# AE822FA0E5597LS0_CM55_HP_View register map
Vendor: Alif Semiconductor; Series: E8; File version: 1.0
CPU: CM55 r1p0, selectable endian, MPU, FPU, double-precision FPU, DSP, VTOR, 8 interrupt priority bits, 1 SAU regions
Registers are 32-bit, read-write, reset 0x0 unless marked. A register's access mark holds for its fields unless they carry their own. Offsets are from the block's base; [hi:lo] are bit positions; {n}, {i} and the like mark numbered series; 'fields as' and 'values as' point back to an identical list.

## LPI2S
Base 0x43001000
Same registers: I2S0 0x49014000, I2S1 0x49015000, I2S2 0x49016000, I2S3 0x49017000
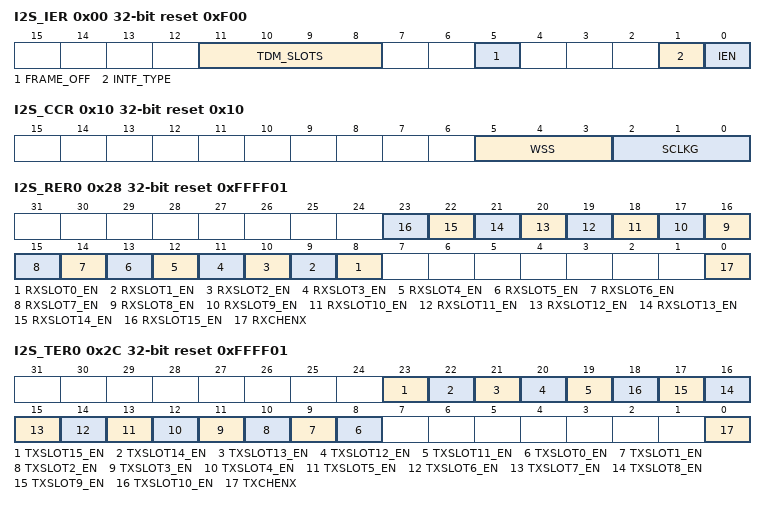
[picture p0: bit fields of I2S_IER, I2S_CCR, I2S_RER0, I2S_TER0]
0x00 I2S_IER reset 0xF00 — I2S Enable Register
  [11:8] TDM_SLOTS — TDM Slots. These bits are used to program the number of receive and transmit slots in a TDM frame. Programmed number of slots must be less than or equal to the number of slots in a TDM frame - 1. If the selected number of slots is greater than the number of slots in a TDM frame - 1, the number of slots defaults back to the number of slots in a TDM frame - 1. The I2S module must be disabled prior to any changes in this field (I2S_IER[IEN] = 0x0).
    0=1 slot in a TDM frame; {v}={v+1} slots in a TDM frame (v=1..15)
  [5] FRAME_OFF — Frame Offset. This bit specifies the TDM Interface frame offset. The I2S module must be disabled prior to any changes in this field (I2S_IER[IEN] = 0x0).
    0=0 SCLK cycle; 1=1 SCLK cycle
  [1] INTF_TYPE — I2S Audio Interface Type. The I2S module must be disabled prior to any changes in this field (I2S_IER[IEN] = 0x0).
    0=Standard I2S Interface; 1=TDM Interface
  [0] IEN — I2S Enable. This bit enables or disables the I2S module. Disabling this bit (I2S_IER[IEN] = 0x0) overrides any other block or channel enables, and flushes all FIFOs. For more information about how this bit affects the other I2S blocks, refer to Section I2S Enable.
    0=I2S disabled; 1=I2S enabled
0x04 I2S_IRER — I2S Receiver Block Enable Register
  [0] RXEN — Receiver Block Enable. This bit enables or disables the Receiver block. Disabling this bit (I2S_IRER[RXEN] = 0x0) overrides the receive channel enables. For more information about the Receiver block, refer to Section I2S as a Receiver. Note: When the I2S module is configured with TDM Interface support, the number of channels are always fixed to one and it is always enabled.
    0=Receiver disabled; 1=Receiver enabled
0x08 I2S_ITER — I2S Transmitter Block Enable Register
  [0] TXEN — Transmitter Block Enable. This bit enables or disables the Transmitter block. Disabling this bit (I2S_ITER[TXEN] = 0x0) overrides the transmit channel enables. For more information about the Transmitter block, refer to Section I2S as a Transmitter. Note: When the I2S module is configured with TDM Interface support, the number of channels are always fixed to one and it is always enabled.
    0=Transmitter disabled; 1=Transmitter enabled
0x0C I2S_CER — Clock Enable Register
  [0] CLKEN — Clock Generation Enable or Disable. This bit enables or disables the clock generation signals when the I2S module is a master: SCLK_EN, WS_OUT, and SCLK_GATE. For more information about clock generation, refer to Section I2S Clocks.
    0=Clock generation disabled; 1=Clock generation enabled
0x10 I2S_CCR reset 0x10 — Clock Configuration Register
  [5:3] WSS — Word Select Size. This bit field is used to program the number of SCLK cycles for which the word select line (WS_OUT) stays in the left or right sample mode. The I2S Clock Generation block must be disabled (I2S_CER[CLKEN] = 0x0) prior to any changes in this value.
    0=16 SCLK cycles; 1=24 SCLK cycles; 2=32 SCLK cycles; 3=64 SCLK cycles; 4=128 SCLK cycles; 5=256 SCLK cycles
  [2:0] SCLKG — SCLK Gating. This bit field is used to program the gating of SCLK. The programmed gating value must be less than or equal to the largest configured (programmed) audio resolution to prevent the truncating of Rx/Tx data. The I2S Clock Generation block must be disabled (I2S_CER[CLKEN] = 0x0) before making any changes in this value.
    0=Clock gating is disabled; 1=Gating after 12 SCLK cycles; 2=Gating after 16 SCLK cycles; 3=Gating after 20 SCLK cycles; 4=Gating after 24 SCLK cycles; 5=Gating after 32 SCLK cycles
0x14 I2S_RXFFR — Receiver Block FIFO Reset Register
  [0] RXFFR wo — Receiver FIFO Reset. Writing a 0x1 to this bit flushes all the Rx FIFOs (this is a self clearing bit). The Receiver block must be disabled before writing to this bit.
    0=Does not flush the Rx FIFO; 1=Flushes the Rx FIFO
0x18 I2S_TXFFR — Transmitter Block FIFO Reset Register
  [0] TXFFR wo — Transmitter FIFO Reset. Writing a 0x1 to this bit flushes all the Tx FIFOs (this is a self clearing bit). The Transmitter block must be disabled prior to writing this bit.
    0=Does not flush the Tx FIFO; 1=Flushes the Tx FIFO
0x1C I2S_SR ro reset 0x1 — Status Register
  [0] TFE — Transmit FIFO Empty. TDM mode (I2S_IER[INTF_TYPE] = 1): When all of the enabled transmit slot FIFOs become completely empty, this bit is set. When any one of the enabled transmit FIFOs contains one or more valid entries, this bit is cleared. Note: When the I2S module is transmitting the last TDM frame, this bit is set along with the last slot in that frame - as the data is popped with it. Hence, user must wait for one slot length, 32 cycles (to ensure that last slot data is transmitted), to disable the interface. I2S mode (I2S_IER[INTF_TYPE] = 0x0): When left and right transmit FIFOs are completely empty, this bit is set. When the left or right transmit FIFO contains one or more valid entries, this bit is cleared. Note: When the I2S module is transmitting the last I2S frame, this bit is set along with the right data transmission in that frame - as the data is popped with it. Hence, user must wait for one word select length (to ensure the right data is transmitted), to disable the interface. This bit field does not request an interrupt.
    0=Transmit FIFO is not empty; 1=Transmit FIFO is empty
0x20 I2S_LRBR0 ro — Left Receive Buffer Register 0
  [31:0] LRBRX — The left stereo data received serially from the receive channel input (SDI). If the Rx FIFO is full and the two-stage read operation (for instance, a read from the I2S_LRBR0[LRBRX] bit field followed by a read from the I2S_RRBR0[RRBRX] bit field) is not performed before the start of the next stereo pair, then the new data is lost and an overrun interrupt occurs (data already in the Rx FIFO is preserved). Note: Before reading this register again, the right stereo data must be read from the I2S_RRBR0[RRBRX] bit field or the status (interrupts) will not be valid.
0x20 I2S_LTHR0 wo (alternate view of I2S_LRBR0) — Left Transmit Holding Register 0
  [31:0] LTHRX — The left stereo data to be transmitted serially through the transmit channel output (SDO) is written through this bit field. Writing is a two-stage process: 1. A write to this bit field passes the left stereo sample to the transmitter. 2. This must be followed by writing the right stereo sample to the I2S_RTHR0[RTHRX] bit field. Note: Data must only be written to the FIFO when it is not full. Any attempt to write to a full FIFO results in that data being lost and an overrun interrupt being generated.
0x24 I2S_RRBR0 ro — Right Receive Buffer Register 0
  [31:0] RRBRX — The right stereo data received serially from the receive channel input (SDI) is read through this bit field. If the Rx FIFO is full and the two-stage read operation (for instance, read from the I2S_LRBR0[LRBRX] bit field followed by a read from the I2S_RRBR0[RRBRX] bit field) is not performed before the start of the next stereo pair, then the new data is lost and an overrun interrupt occurs (data already in the Rx FIFO is preserved). Note: Prior to reading this bit field, the left stereo data must be read from the I2S_LRBR0[LRBRX] bit field, or the status (interrupts) will not be valid.
0x24 I2S_RTHR0 wo (alternate view of I2S_RRBR0) — Right Transmit Holding Register
  [31:0] RTHRX — The right stereo data to be transmitted serially through the transmit channel output (SDO) is written through this bit field. Writing is a two-stage process: 1. A left stereo sample must be written to the I2S_LTHR0[LTHRX] bit field. 2. A write to this bit field passes the right stereo sample to the transmitter. Note: Data should only be written to the FIFO when it is not full. Any attempt to write to a full FIFO results in that data being lost and an overrun interrupt being generated.
0x28 I2S_RER0 reset 0xFFFF01 — Receive Enable Register 0
  [n+8] RXSLOT{n}_EN (n=0..15) — Receiver slot {n} enable. Writing a 1/0 into this bit enables/disables the slot.
    0=Slot {n} Disable; 1=Slot {n} Enable
  [0] RXCHENX ro — Receive Channel Enable. This bit enables/disables a receive channel, independently of all other channels. On enable, the channel begins receiving on the next left stereo cycle. A global disable of the I2S module (I2S_IER[IEN] = 0x0) or the Receiver block (I2S_IRER[RXEN] = 0x0) overrides this value. When the I2S module is configured with TDM Interface support, the number of channels are always fixed to one and it is always enabled.
    0=Receive channel disable; 1=Receive channel enable
0x2C I2S_TER0 reset 0xFFFF01 — Transmit Enable Register 0
  [23] TXSLOT15_EN — Transmitter slot 15 enable. Writing a 1/0 into this bit enables/disables the slot.
    0=Slot 15 Disable; 1=Slot 15 Enable
  [22] TXSLOT14_EN — Transmitter slot 14 enable. Writing a 1/0 into this bit enables/disables the slot.
    0=Slot 14 Disable; 1=Slot 14 Enable
  [21] TXSLOT13_EN — Transmitter slot 13 enable. Writing a 1/0 into this bit enables/disables the slot.
    0=Slot 13 Disable; 1=Slot 13 Enable
  [20] TXSLOT12_EN — Transmitter slot 12 enable register. Writing a 1/0 into this bit enables/disables the slot.
    0=Slot 12 Disable; 1=Slot 12 Enable
  [19] TXSLOT11_EN — Transmitter slot 11 enable register. Writing a 1/0 into this bit enables/disables the slot.
    0=Slot 11 Disable; 1=Slot 11 Enable
  [n+8] TXSLOT{n}_EN (n=0..10) — Transmitter slot {n} enable. Writing a 1/0 into this bit enables/disables the slot.
    0=Slot {n} Disable; 1=Slot {n} Enable
  [0] TXCHENX ro — Transmit Channel Enable. This bit enables/disables a transmit channel, independently of all other channels. On enable, the channel begins transmitting on the next left stereo cycle. A global disable of the I2S module (I2S_IER[IEN] = 0x0 or the Transmitter block (I2S_ITER[TXEN] = 0x0) overrides this value. When the I2S module is configured with TDM Interface support, the number of channels are always fixed to one and it is always enabled.
    0=Transmit channel disable; 1=Transmit channel enable
0x30 I2S_RCR0 reset 0x5 — Receive Configuration Register 0
  [2:0] WLEN — This bit field is used to program the desired data resolution of the receiver and enables the LSB of the incoming left (or right) word to be placed in the LSB of the I2S_LRBR0[LRBRX] (or I2S_RRBR0[RRBRX]) bit field. Programmed data resolution must be less than or equal to the I2S_COMP_PARAM_2[I2S_RX_WORDSIZE_x] bit field value, where x = 0 to 3. If the selected resolution is greater than the I2S_COMP_PARAM_2[I2S_RX_WORDSIZE_x] bit field value, the receive channel defaults back to the to the maximum audio data resolution supported. The channel must be disabled prior to any changes in this value (I2S_RER0[RXCHENX] = 0x0). Note: When the I2S module is configured with TDM Interface support, the number of channels are always fixed to one and it is always enabled. Hence, with TDM Interface configuration, the receiver block must be disabled prior to any changes in this field's value (I2S_IRER[RXEN] = 0x0).
    0=Ignore the word length; 1=12-bit data resolution of the receiver; 2=16-bit data resolution of the receiver; 3=20-bit data resolution of the receiver; 4=24-bit data resolution of the receiver; 5=32-bit data resolution of the receiver
0x34 I2S_TCR0 reset 0x5 — Transmit Configuration Register 0
  [2:0] WLEN — This bit field is used to program the desired data resolution of the transmitter and ensures the MSB of the data is transmitted first. Programmed resolution must be less than or equal to the I2S_COMP_PARAM_1[I2S_TX_WORDSIZE_x] bit field value, where x = 0 to 3. If the selected resolution is greater than the I2S_COMP_PARAM_1[I2S_TX_WORDSIZE_x] bit field value, the transmit channel defaults back to the to the maximum audio data resolution supported. The channel must be disabled prior to any changes in this value (I2S_TER0[TXCHENX] = 0x0). Note: When the I2S module is configured with TDM Interface support, the number of channels are always fixed to one and it is always enabled. Hence, with TDM Interface configuration, the transmitter block must be disabled prior to any changes in this field's value (I2S_ITER[TXEN] = 0x0).
    0=Ignore the word length; 1=12-bit data resolution of the transmitter; 2=16-bit data resolution of the transmitter; 3=20-bit data resolution of the transmitter; 4=24-bit data resolution of the transmitter; 5=32-bit data resolution of the transmitter
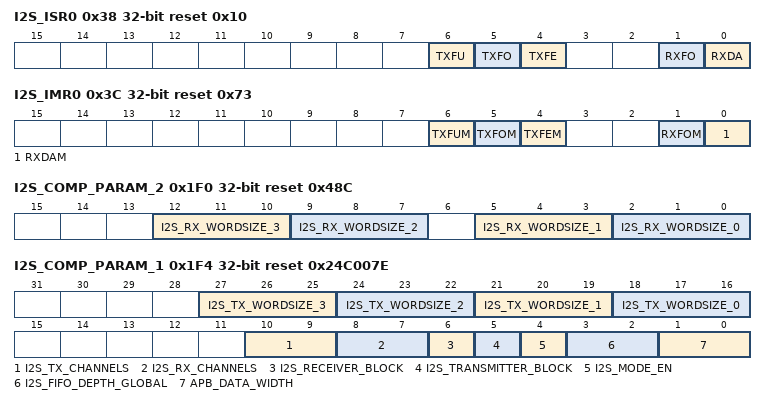
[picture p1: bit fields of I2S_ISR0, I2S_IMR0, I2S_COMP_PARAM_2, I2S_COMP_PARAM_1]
0x38 I2S_ISR0 ro reset 0x10 — Interrupt Status Register 0
  [6] TXFU — Indicates TX FIFO Underrun Interrupt generated for Transmit Channel x.
    0=No TX FIFO underrun; 1=TX FIFO underrun
  [5] TXFO — Status of Data Overrun Interrupt for the Tx Channel. This bit specifies whether the Tx FIFO write is valid or an overrun (attempt to write to full Tx FIFO).
    0=Tx FIFO write valid; 1=Tx FIFO write overrun
  [4] TXFE — Status of Transmit Empty Trigger Interrupt. This bit specifies whether the Tx FIFO trigger level has reached or not (Tx FIFO is empty).
    0=Tx FIFO trigger level is reached; 1=Tx FIFO trigger level is not reached
  [1] RXFO — Status of Data Overrun Interrupt for the Rx Channel. Incoming data lost due to a full Rx FIFO.
    0=Rx FIFO write valid; 1=Rx FIFO write overrun
  [0] RXDA — Status of Receive Data Available Interrupt. This bit denotes the status of the Rx FIFO trigger level.
    0=Rx FIFO trigger level is not reached; 1=Rx FIFO trigger level is reached
0x3C I2S_IMR0 reset 0x73 — Interrupt Mask Register 0
  [6] TXFUM — Mask TX FIFO Underrun interrupt. This bit masks or unmasks a Tx FIFO Underrun interrupt.
    1=Masks TX FIFO Underrun interrupt; 0=Unmasks TX FIFO Underrun interrupt
  [5] TXFOM — Mask Tx FIFO Overrun Interrupt. This bit masks or unmasks a Tx FIFO Overrun interrupt.
    1=Masks Tx FIFO Overrun interrupt; 0=Unmasks Tx FIFO Overrun interrupt
  [4] TXFEM — Mask Tx FIFO Empty Interrupt. This bit masks or unmasks a Tx FIFO Empty interrupt.
    1=Masks Tx FIFO Empty interrupt; 0=Unmasks Tx FIFO Empty Interrupt
  [1] RXFOM — Mask Rx FIFO Overrun Interrupt. This bit masks or unmasks an Rx FIFO Overrun interrupt.
    1=Masks Rx FIFO Overrun interrupt; 0=Unmasks Rx FIFO Overrun interrupt
  [0] RXDAM — Mask Rx FIFO Data Available Interrupt. This bit masks or unmasks an Rx FIFO Data Available interrupt.
    1=Masks Rx FIFO data available interrupt; 0=Unmasks Rx FIFO data available interrupt
0x40 I2S_ROR0 ro — Receive Overrun Register 0
  [0] RXCHO — Read this bit to clear the Rx FIFO Data Overrun interrupt.
    0=Rx FIFO write valid; 1=Rx FIFO write overrun
0x44 I2S_TICR0 ro — Transmit Interrupt Clear Register 0
  [0] TXCHOU — Read this bit to clear TX FIFO Data Overrun or Data Underrun interrupts.
    0=No TX FIFO overrun or underrun; 1=TX FIFO overrun or underrun
0x48 I2S_RFCR0 reset 0x3 — Receive FIFO Configuration Register 0
  [3:0] RXCHDT — This bit field programs the trigger level in the Rx FIFO at which the Received Data Available interrupt and DMA request is generated (Trigger Level = Programmed Value + 1). Valid values of the I2S_RFCR0[RXCHDT] bit field: 0 to Rx FIFO depth - 1. If an illegal value is programmed, this bit field saturates to Rx FIFO depth - 1. For more information about FIFO depth, refer to Section I2S Overview. The channel must be disabled prior to any changes in this value (I2S_RER0[RXCHENX] = 0x0). Note: When the I2S module is configured with TDM Interface support, the number of channels are always fixed to one and it is always enabled. Hence, with TDM Interface configuration, the receiver block must be disabled prior to any changes in this field's value (I2S_IRER[RXEN] = 0x0).
    {v}=Interrupt trigger and DMA request asserted when FIFO level is {v+1} (v=0..15)
0x4C I2S_TFCR0 reset 0x3 — Transmit FIFO Configuration Register 0
  [3:0] TXCHET — This bit field programs the trigger level in the Tx FIFO at which the Empty Threshold Reached interrupt and DMA request is generated (Trigger Level = TXCHET). Valid values of the I2S_TFCR0[TXCHET] bit field: 0 to Tx FIFO depth - 1. If an illegal value is programmed, this bit field saturates to Tx FIFO depth - 1. The channel must be disabled prior to any changes in this value (I2S_TER0[TXCHENX] = 0x0). Note: When the I2S module is configured with TDM Interface support, the number of channels are always fixed to one and it is always enabled. Hence, with TDM Interface configuration, the transmitter block must be disabled prior to any changes in this field's value (I2S_ITER[TXEN] = 0x0).
    values as I2S_RFCR0.RXCHDT
0x50 I2S_RFF0 — Receive FIFO Flush Register 0
  [0] RXCHFR wo — Receive Channel FIFO Reset. Writing a 0x1 to this bit flushes the channel Rx FIFO (this is a self clearing bit). The Rx channel or block must be disabled prior to writing to this bit. In TDM mode, writing a 1 to this register flushes all Slot FIFOs.
    0=Does not flush the channel Rx FIFO; 1=Flushes the channel Rx FIFO
0x54 I2S_TFF0 — Transmit FIFO Flush Register 0
  [0] TXCHFR wo — Transmit Channel FIFO Reset. Writing a 0x1 to this bit flushes the channel Tx FIFO (this is a self clearing bit). The Tx channel or block must be disabled prior to writing to this bit. In TDM mode, writing a 1 to this register flushes all Slot FIFOs.
    0=Does not flush TX FIFO of the channel; 1=Flushes TX FIFO of the channel
0x1C0 I2S_RXDMA ro — Receiver Block DMA Register
  [31:0] RXDMA — Receiver Block DMA. In Standard I2S Interface Mode, these bits are used to cycle repeatedly through the enabled receive channels (from lowest numbered to highest), reading stereo data pairs. In TDM Interface Mode, these bits are used to cycle repeatedly read through the enabled receive slots (from lowest numbered to highest). For more information about the supported receive channels, refer to Section I2S Overview.
0x1C4 I2S_RRXDMA — Reset Receiver Block DMA Register
  [0] RRXDMA wo — Reset Receiver Block DMA Register. Writing a 1 to this self-clearing register resets the I2S_RXDMA register mid-cycle to point to the lowest enabled Receive channel. Note: Writing to this register has no effect if the component is performing a stereo pair read (such as, when left stereo data has been read but not right stereo data). When the I2S module is programmed for TDM support, writing a 1 to this self-clearing register resets the I2S_RXDMA register mid-cycle to point to the lowest enabled Receive slot.
    1=Reset Receiver Block DMA Register
0x1C8 I2S_TXDMA wo — Transmitter Block DMA Register
  [31:0] TXDMA — Transmitter Block DMA. These bits are used to allow writing of stereo data pairs to the enabled transmit channel. In TDM Interface mode, these bits are used to cycle repeatedly write through the enabled transmit slots (from lowest numbered to highest). For more information about the supported transmit channels, refer to Section I2S Overview.
0x1CC I2S_RTXDMA — Reset Transmitter Block DMA Register
  [0] RTXDMA wo — Reset Transmitter Block DMA Register. Writing a 1 to this self-clearing register resets the TXDMA register mid-cycle to point to the lowest enabled Transmit channel. Note: This register has no effect in the middle of a stereo pair write (such as, when left stereo data has been written but not right stereo data). When the I2S is programmed for TDM support, writing a 1 to this self-clearing register resets the I2S_TXDMA register mid-cycle to point to the lowest enabled transmit slot.
    1=Reset Transmitter Block DMA Register
0x1F0 I2S_COMP_PARAM_2 ro reset 0x48C — Module Configuration Register 2
  [12:10] I2S_RX_WORDSIZE_3 — These bits specify the Rx resolution for WORDSIZE_3.
    1=16-bit Resolution
  [9:7] I2S_RX_WORDSIZE_2 — These bits specify the Rx resolution for WORDSIZE_2.
    1=16-bit Resolution
  [5:3] I2S_RX_WORDSIZE_1 — These bits specify the Rx resolution for WORDSIZE_1.
    1=16-bit Resolution
  [2:0] I2S_RX_WORDSIZE_0 — These bits specify the Rx resolution for WORDSIZE_0.
    4=32-bit Resolution
0x1F4 I2S_COMP_PARAM_1 ro reset 0x24C007E — Module Configuration Register 1
  [27:25] I2S_TX_WORDSIZE_3 — These bits specify the Tx resolution for WORDSIZE_3.
    1=16-bit Resolution
  [24:22] I2S_TX_WORDSIZE_2 — These bits specify the Tx resolution for WORDSIZE_2.
    1=16-bit Resolution
  [21:19] I2S_TX_WORDSIZE_1 — These bits specify the Tx resolution for WORDSIZE_1.
    1=16-bit Resolution
  [18:16] I2S_TX_WORDSIZE_0 — These bits specify the Tx resolution for WORDSIZE_0.
    4=32-bit Resolution
  [10:9] I2S_TX_CHANNELS — These bits specify the number of Tx channels.
    0=1 x Transmit channel
  [8:7] I2S_RX_CHANNELS — These bits specify the number of Rx channels.
    0=1 x Receive channel
  [6] I2S_RECEIVER_BLOCK — This bit specifies whether the receiver block is enabled or not.
    1=Receiver block is enabled
  [5] I2S_TRANSMITTER_BLOCK — This bit specifies whether the transmitter block is enabled or not.
    1=Transmitter block is enabled
  [4] I2S_MODE_EN — This bit specifies whether the Master mode is enabled or not.
    1=Master mode is enabled
  [3:2] I2S_FIFO_DEPTH_GLOBAL — These bits specify the FIFO depth for Tx and Rx channels.
    3=FIFO depth is equals to 16 for Tx and Rx channels
  [1:0] APB_DATA_WIDTH — These bits specify the APB data width.
    2=APB data width of 32 bits
0x1F8 I2S_COMP_VERSION ro reset 0x3131332A — Component Parameter Register
  [31:0] I2S_COMP_VERSION — Module component version
0x1FC I2S_COMP_TYPE ro reset 0x445701A0 — Component Type Register
  [31:0] I2S_COMP_TYPE — Component type
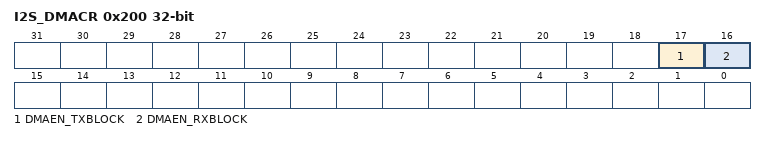
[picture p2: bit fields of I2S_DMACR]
0x200 I2S_DMACR — DMA Control Register
  [17] DMAEN_TXBLOCK — DMA enable for the Transmit block. This bit enables or disables the DMA handshake logic for the transmitter block.
    0=DMA disabled for the transmit block; 1=DMA enabled for the transmit block
  [16] DMAEN_RXBLOCK — DMA enable for the Receive block. This bit enables or disables the DMA handshake logic for the receiver block.
    0=DMA disabled for the receiver block; 1=DMA enabled for the receiver block
{0x224+4i} I2S_RSLOT[{i}] (i=0..15) ro — Receive Slot (n) Buffer Register
  [31:0] RSLOTN — The slot (n) data received serially from the receiver input (SDI line). If the RX FIFO is full and read operation is not performed before the start of the next slot data, then the new data is lost and an overrun interrupt occurs (data already in the RX FIFO is preserved).
{0x224+4i} I2S_TSLOT[{i}] (i=0..15) ro (alternate view of I2S_RSLOT[{i}]) — Transmit Slot (n) Buffer Register
  [31:0] TSLOTN — The slot (n) data to be transmitted serially through the transmitter output (SDO line) is written through this register. Data must only be written to the FIFO when it is not full. Any attempt to write to a full FIFO results in that data being lost and an overrun interrupt being generated.
